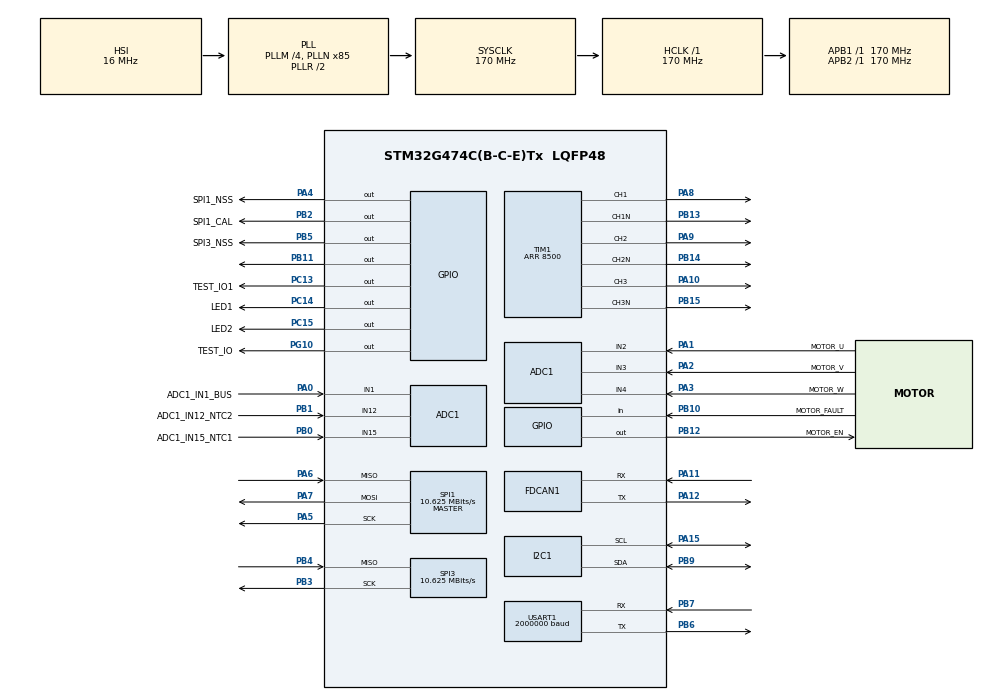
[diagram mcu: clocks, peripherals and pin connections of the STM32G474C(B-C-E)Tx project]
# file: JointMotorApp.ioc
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ADC1.Channel-0\#ChannelRegularConversion=ADC_CHANNEL_1
ADC1.Channel-6\#ChannelRegularConversion=ADC_CHANNEL_15
ADC1.Channel-7\#ChannelRegularConversion=ADC_CHANNEL_12
ADC1.ContinuousConvMode=DISABLE
ADC1.DMAContinuousRequests=ENABLE
ADC1.EOCSelection=ADC_EOC_SEQ_CONV
ADC1.EnableInjectedConversion=ENABLE
ADC1.ExternalTrigInjecConv=ADC_EXTERNALTRIGINJEC_T1_CC4
ADC1.InjNumberOfConversion=3
ADC1.InjectedChannel-3\#ChannelInjectedConversion=ADC_CHANNEL_2
ADC1.InjectedChannel-4\#ChannelInjectedConversion=ADC_CHANNEL_3
ADC1.InjectedChannel-5\#ChannelInjectedConversion=ADC_CHANNEL_4
ADC1.InjectedOffsetNumber-3\#ChannelInjectedConversion=ADC_OFFSET_NONE
ADC1.InjectedOffsetNumber-4\#ChannelInjectedConversion=ADC_OFFSET_NONE
ADC1.InjectedOffsetNumber-5\#ChannelInjectedConversion=ADC_OFFSET_NONE
ADC1.InjectedRank-3\#ChannelInjectedConversion=1
ADC1.InjectedRank-4\#ChannelInjectedConversion=2
ADC1.InjectedRank-5\#ChannelInjectedConversion=3
ADC1.InjectedSamplingTime-3\#ChannelInjectedConversion=ADC_SAMPLETIME_12CYCLES_5
ADC1.InjectedSamplingTime-4\#ChannelInjectedConversion=ADC_SAMPLETIME_12CYCLES_5
ADC1.InjectedSamplingTime-5\#ChannelInjectedConversion=ADC_SAMPLETIME_12CYCLES_5
ADC1.NbrOfConversion=3
ADC1.NbrOfConversionFlag=1
ADC1.OffsetNumber-0\#ChannelRegularConversion=ADC_OFFSET_NONE
ADC1.OffsetNumber-6\#ChannelRegularConversion=ADC_OFFSET_NONE
ADC1.OffsetNumber-7\#ChannelRegularConversion=ADC_OFFSET_NONE
ADC1.Rank-0\#ChannelRegularConversion=1
ADC1.Rank-6\#ChannelRegularConversion=2
ADC1.Rank-7\#ChannelRegularConversion=3
ADC1.SamplingTime-0\#ChannelRegularConversion=ADC_SAMPLETIME_47CYCLES_5
ADC1.SamplingTime-6\#ChannelRegularConversion=ADC_SAMPLETIME_47CYCLES_5
ADC1.SamplingTime-7\#ChannelRegularConversion=ADC_SAMPLETIME_47CYCLES_5
ADC1.master=1
Dma.ADC1.2.Direction=DMA_PERIPH_TO_MEMORY
Dma.ADC1.2.EventEnable=DISABLE
Dma.ADC1.2.Instance=DMA1_Channel3
Dma.ADC1.2.MemDataAlignment=DMA_MDATAALIGN_WORD
Dma.ADC1.2.MemInc=DMA_MINC_ENABLE
Dma.ADC1.2.Mode=DMA_CIRCULAR
Dma.ADC1.2.PeriphDataAlignment=DMA_PDATAALIGN_HALFWORD
Dma.ADC1.2.PeriphInc=DMA_PINC_DISABLE
Dma.ADC1.2.Polarity=HAL_DMAMUX_REQ_GEN_RISING
Dma.ADC1.2.Priority=DMA_PRIORITY_LOW
Dma.ADC1.2.RequestNumber=1
Dma.ADC1.2.SignalID=NONE
Dma.ADC1.2.SyncEnable=DISABLE
Dma.ADC1.2.SyncPolarity=HAL_DMAMUX_SYNC_NO_EVENT
Dma.ADC1.2.SyncRequestNumber=1
Dma.ADC1.2.SyncSignalID=NONE
Dma.Request0=USART1_RX
Dma.Request1=USART1_TX
Dma.Request2=ADC1
Dma.USART1_RX.0.Direction=DMA_PERIPH_TO_MEMORY
Dma.USART1_RX.0.EventEnable=DISABLE
Dma.USART1_RX.0.Instance=DMA1_Channel1
Dma.USART1_RX.0.MemDataAlignment=DMA_MDATAALIGN_BYTE
Dma.USART1_RX.0.MemInc=DMA_MINC_ENABLE
Dma.USART1_RX.0.Mode=DMA_CIRCULAR
Dma.USART1_RX.0.PeriphDataAlignment=DMA_PDATAALIGN_BYTE
Dma.USART1_RX.0.PeriphInc=DMA_PINC_DISABLE
Dma.USART1_RX.0.Polarity=HAL_DMAMUX_REQ_GEN_RISING
Dma.USART1_RX.0.Priority=DMA_PRIORITY_LOW
Dma.USART1_RX.0.RequestNumber=1
Dma.USART1_RX.0.SignalID=NONE
Dma.USART1_RX.0.SyncEnable=DISABLE
Dma.USART1_RX.0.SyncPolarity=HAL_DMAMUX_SYNC_NO_EVENT
Dma.USART1_RX.0.SyncRequestNumber=1
Dma.USART1_RX.0.SyncSignalID=NONE
Dma.USART1_TX.1.Direction=DMA_MEMORY_TO_PERIPH
Dma.USART1_TX.1.EventEnable=DISABLE
Dma.USART1_TX.1.Instance=DMA1_Channel2
Dma.USART1_TX.1.MemDataAlignment=DMA_MDATAALIGN_BYTE
Dma.USART1_TX.1.MemInc=DMA_MINC_ENABLE
Dma.USART1_TX.1.Mode=DMA_NORMAL
Dma.USART1_TX.1.PeriphDataAlignment=DMA_PDATAALIGN_BYTE
Dma.USART1_TX.1.PeriphInc=DMA_PINC_DISABLE
Dma.USART1_TX.1.Polarity=HAL_DMAMUX_REQ_GEN_RISING
Dma.USART1_TX.1.Priority=DMA_PRIORITY_LOW
Dma.USART1_TX.1.RequestNumber=1
Dma.USART1_TX.1.SignalID=NONE
Dma.USART1_TX.1.SyncEnable=DISABLE
Dma.USART1_TX.1.SyncPolarity=HAL_DMAMUX_SYNC_NO_EVENT
Dma.USART1_TX.1.SyncRequestNumber=1
Dma.USART1_TX.1.SyncSignalID=NONE
FDCAN1.CalculateBaudRateNominal=999999
FDCAN1.CalculateTimeBitNominal=1000
FDCAN1.CalculateTimeQuantumNominal=58.82352941176471
FDCAN1.ClockDivider=FDCAN_CLOCK_DIV2
FDCAN1.NominalPrescaler=5
FDCAN1.NominalTimeSeg1=12
FDCAN1.NominalTimeSeg2=4
FREERTOS.Tasks01=defaultTask,0,128,StartDefaultTask,Default,NULL,Dynamic,NULL,NULL
FREERTOS.configTOTAL_HEAP_SIZE=16384
I2C1.Timing=0x40B285C2
Mcu.Family=STM32G4
Mcu.Name=STM32G474C(B-C-E)Tx
Mcu.Package=LQFP48
NVIC.ADC1_2_IRQn=true\:5\:0\:false\:false\:true\:true\:true\:true\:true
NVIC.DMA1_Channel1_IRQn=true\:5\:0\:false\:false\:true\:true\:false\:true\:true
NVIC.DMA1_Channel2_IRQn=true\:5\:0\:false\:false\:true\:true\:false\:true\:true
NVIC.DMA1_Channel3_IRQn=true\:5\:0\:false\:false\:true\:true\:false\:true\:true
NVIC.FDCAN1_IT0_IRQn=true\:5\:0\:false\:false\:true\:true\:true\:true\:true
NVIC.PriorityGroup=NVIC_PRIORITYGROUP_4
NVIC.TIM1_BRK_TIM15_IRQn=true\:5\:0\:false\:false\:true\:true\:true\:true\:true
NVIC.TIM1_UP_TIM16_IRQn=true\:5\:0\:false\:false\:true\:true\:true\:true\:true
NVIC.TIM2_IRQn=true\:5\:0\:false\:false\:true\:true\:true\:true\:true
NVIC.TIM5_IRQn=true\:5\:0\:false\:false\:true\:true\:true\:true\:true
NVIC.TIM7_DAC_IRQn=true\:15\:0\:false\:false\:true\:false\:false\:true\:true
NVIC.TimeBase=TIM7_DAC_IRQn
NVIC.TimeBaseIP=TIM7
NVIC.USART1_IRQn=true\:5\:0\:false\:false\:true\:true\:true\:true\:true
PA0.GPIO_Label=ADC1_IN1_BUS
PA0.Mode=IN1-Single-Ended
PA0.Signal=ADC1_IN1
PA1.GPIO_Label=MOTOR_U
PA1.Mode=IN2-Single-Ended
PA1.Signal=ADC1_IN2
PA10.Signal=S_TIM1_CH3
PA11.Mode=FDCAN_Activate
PA11.Signal=FDCAN1_RX
PA12.Mode=FDCAN_Activate
PA12.Signal=FDCAN1_TX
PA13.Mode=Serial_Wire
PA13.Signal=SYS_JTMS-SWDIO
PA14.Mode=Serial_Wire
PA14.Signal=SYS_JTCK-SWCLK
PA15.Mode=I2C
PA15.Signal=I2C1_SCL
PA2.GPIO_Label=MOTOR_V
PA2.Mode=IN3-Single-Ended
PA2.Signal=ADC1_IN3
PA3.GPIO_Label=MOTOR_W
PA3.Mode=IN4-Single-Ended
PA3.Signal=ADC1_IN4
PA4.GPIO_Label=SPI1_NSS
PA4.Signal=GPIO_Output
PA5.Mode=Full_Duplex_Master
PA5.Signal=SPI1_SCK
PA6.Mode=Full_Duplex_Master
PA6.Signal=SPI1_MISO
PA7.Mode=Full_Duplex_Master
PA7.Signal=SPI1_MOSI
PA8.Signal=S_TIM1_CH1
PA9.Signal=S_TIM1_CH2
PB0.GPIO_Label=ADC1_IN15_NTC1
PB0.Mode=IN15-Single-Ended
PB0.Signal=ADC1_IN15
PB1.GPIO_Label=ADC1_IN12_NTC2
PB1.Mode=IN12-Single-Ended
PB1.Signal=ADC1_IN12
PB10.GPIO_Label=MOTOR_FAULT
PB10.Signal=GPIO_Input
PB11.Signal=GPIO_Output
PB12.GPIO_Label=MOTOR_EN
PB12.Signal=GPIO_Output
PB13.Mode=PWM Generation1 CH1 CH1N
PB13.Signal=TIM1_CH1N
PB14.Mode=PWM Generation2 CH2 CH2N
PB14.Signal=TIM1_CH2N
PB15.Mode=PWM Generation3 CH3 CH3N
PB15.Signal=TIM1_CH3N
PB2.GPIO_Label=SPI1_CAL
PB2.Signal=GPIO_Output
PB3.Mode=RX_Only_Simplex_Unidirect_Master
PB3.Signal=SPI3_SCK
PB4.Mode=RX_Only_Simplex_Unidirect_Master
PB4.Signal=SPI3_MISO
PB5.GPIO_Label=SPI3_NSS
PB5.Signal=GPIO_Output
PB6.Mode=Asynchronous
PB6.Signal=USART1_TX
PB7.Mode=Asynchronous
PB7.Signal=USART1_RX
PB9.Mode=I2C
PB9.Signal=I2C1_SDA
PC13.GPIO_Label=TEST_IO1
PC13.Signal=GPIO_Output
PC14-OSC32_IN.GPIO_Label=LED1
PC14-OSC32_IN.Signal=GPIO_Output
PC15-OSC32_OUT.GPIO_Label=LED2
PC15-OSC32_OUT.Signal=GPIO_Output
PF0-OSC_IN.Mode=HSE-External-Oscillator
PF0-OSC_IN.Signal=RCC_OSC_IN
PF1-OSC_OUT.Mode=HSE-External-Oscillator
PF1-OSC_OUT.Signal=RCC_OSC_OUT
PG10-NRST.GPIO_Label=TEST_IO
PG10-NRST.Signal=GPIO_Output
ProjectManager.HeapSize=0x200
ProjectManager.StackSize=0x400
ProjectManager.TargetToolchain=MDK-ARM V5.32
RCC.ADC12Freq_Value=170000000
RCC.ADC345Freq_Value=170000000
RCC.AHBFreq_Value=170000000
RCC.APB1Freq_Value=170000000
RCC.APB1TimFreq_Value=170000000
RCC.APB2Freq_Value=170000000
RCC.APB2TimFreq_Value=170000000
RCC.CortexFreq_Value=170000000
RCC.EXTERNAL_CLOCK_VALUE=12288000
RCC.HCLKFreq_Value=170000000
RCC.HSE_VALUE=8000000
RCC.HSI48_VALUE=48000000
RCC.HSI_VALUE=16000000
RCC.LSE_VALUE=32768
RCC.PLLM=RCC_PLLM_DIV4
RCC.PLLN=85
RCC.SYSCLKFreq_VALUE=170000000
RCC.SYSCLKSource=RCC_SYSCLKSOURCE_PLLCLK
RCC.USBFreq_Value=170000000
RCC.VCOOutputFreq_Value=340000000
SH.S_TIM1_CH1.0=TIM1_CH1,PWM Generation1 CH1 CH1N
SH.S_TIM1_CH2.0=TIM1_CH2,PWM Generation2 CH2 CH2N
SH.S_TIM1_CH3.0=TIM1_CH3,PWM Generation3 CH3 CH3N
SPI1.BaudRatePrescaler=SPI_BAUDRATEPRESCALER_16
SPI1.CLKPhase=SPI_PHASE_2EDGE
SPI1.CLKPolarity=SPI_POLARITY_HIGH
SPI1.CalculateBaudRate=10.625 MBits/s
SPI1.DataSize=SPI_DATASIZE_8BIT
SPI1.Direction=SPI_DIRECTION_2LINES
SPI1.Mode=SPI_MODE_MASTER
SPI1.VirtualType=VM_MASTER
SPI3.BaudRatePrescaler=SPI_BAUDRATEPRESCALER_16
SPI3.CalculateBaudRate=10.625 MBits/s
SPI3.DataSize=SPI_DATASIZE_8BIT
SPI3.Direction=SPI_DIRECTION_2LINES_RXONLY
SPI3.Mode=SPI_MODE_MASTER
SPI3.VirtualType=VM_MASTER
STMicroelectronics.X-CUBE-ALGOBUILD.1.5.0.LibraryCcDSPOoLibraryJjDSPOoLibrary=true
TIM1.Channel-PWM\ Generation1\ CH1\ CH1N=TIM_CHANNEL_1
TIM1.Channel-PWM\ Generation2\ CH2\ CH2N=TIM_CHANNEL_2
TIM1.Channel-PWM\ Generation3\ CH3\ CH3N=TIM_CHANNEL_3
TIM1.Channel-PWM\ Generation4\ No\ Output=TIM_CHANNEL_4
TIM1.CounterMode=TIM_COUNTERMODE_CENTERALIGNED1
TIM1.PeriodNoDither=8500
TIM2.PeriodNoDither=17000
TIM5.PeriodNoDither=17000
USART1.BaudRate=2000000
USART1.VirtualMode-Asynchronous=VM_ASYNC
VP_CORDIC_VS_CORDIC.Mode=CORDIC_Activate
VP_FREERTOS_VS_CMSIS_V1.Mode=CMSIS_V1
VP_STMicroelectronics.X-CUBE-ALGOBUILD_VS_DSPOoLibraryJjLibrary_1.5.0_1.5.0.Mode=DSPOoLibraryJjLibrary
VP_SYS_VS_DBSignals.Mode=DisableDeadBatterySignals
VP_SYS_VS_tim7.Mode=TIM7
VP_TIM1_VS_no_output4.Mode=PWM Generation4 No Output
VP_TIM2_VS_ClockSourceINT.Mode=Internal
VP_TIM5_VS_ClockSourceINT.Mode=Internal
board=custom

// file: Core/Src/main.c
/* USER CODE BEGIN Header */
/**
  ******************************************************************************
  * @file           : main.c
  * @brief          : Main program body
  ******************************************************************************
  * @attention
  *
  * Copyright (c) 2026 STMicroelectronics.
  * All rights reserved.
  *
  * This software is licensed under terms that can be found in the LICENSE file
  * in the root directory of this software component.
  * If no LICENSE file comes with this software, it is provided AS-IS.
  *
  ******************************************************************************
  */
/* USER CODE END Header */
#include "main.h"
#include "cmsis_os.h"
#include "adc.h"
#include "cordic.h"
#include "dma.h"
#include "fdcan.h"
#include "i2c.h"
#include "spi.h"
#include "tim.h"
#include "usart.h"
#include "gpio.h"

/* USER CODE BEGIN Includes */
#include "user_interface.h"
/* USER CODE END Includes */

void SystemClock_Config(void);
void MX_FREERTOS_Init(void);

int main(void)
{

  /* MCU Configuration--------------------------------------------------------*/

  /* Reset of all peripherals, Initializes the Flash interface and the Systick. */
  HAL_Init();

  /* Configure the system clock */
  SystemClock_Config();

  /* Initialize all configured peripherals */
  MX_GPIO_Init();
  MX_DMA_Init();
  MX_ADC1_Init();
  MX_CORDIC_Init();
  MX_I2C1_Init();
  MX_SPI1_Init();
  MX_SPI3_Init();
  MX_USART1_UART_Init();
  MX_FDCAN1_Init();
  MX_TIM1_Init();
  MX_TIM2_Init();
  MX_TIM5_Init();
  /* USER CODE BEGIN 2 */

	user_init();

  /* USER CODE END 2 */

  /* Call init function for freertos objects (in cmsis_os2.c) */
  MX_FREERTOS_Init();

  /* Start scheduler */
  osKernelStart();

  /* We should never get here as control is now taken by the scheduler */

  /* Infinite loop */
	while (1)
	{

	}
}

void SystemClock_Config(void)
{
  RCC_OscInitTypeDef RCC_OscInitStruct = {0};
  RCC_ClkInitTypeDef RCC_ClkInitStruct = {0};

  /** Configure the main internal regulator output voltage
  */
  HAL_PWREx_ControlVoltageScaling(PWR_REGULATOR_VOLTAGE_SCALE1_BOOST);

  /** Initializes the RCC Oscillators according to the specified parameters
  * in the RCC_OscInitTypeDef structure.
  */
  RCC_OscInitStruct.OscillatorType = RCC_OSCILLATORTYPE_HSI;
  RCC_OscInitStruct.HSIState = RCC_HSI_ON;
  RCC_OscInitStruct.HSICalibrationValue = RCC_HSICALIBRATION_DEFAULT;
  RCC_OscInitStruct.PLL.PLLState = RCC_PLL_ON;
  RCC_OscInitStruct.PLL.PLLSource = RCC_PLLSOURCE_HSI;
  RCC_OscInitStruct.PLL.PLLM = RCC_PLLM_DIV4;
  RCC_OscInitStruct.PLL.PLLN = 85;
  RCC_OscInitStruct.PLL.PLLP = RCC_PLLP_DIV2;
  RCC_OscInitStruct.PLL.PLLQ = RCC_PLLQ_DIV2;
  RCC_OscInitStruct.PLL.PLLR = RCC_PLLR_DIV2;
  if (HAL_RCC_OscConfig(&RCC_OscInitStruct) != HAL_OK)
  {
    Error_Handler();
  }

  /** Initializes the CPU, AHB and APB buses clocks
  */
  RCC_ClkInitStruct.ClockType = RCC_CLOCKTYPE_HCLK|RCC_CLOCKTYPE_SYSCLK
                              |RCC_CLOCKTYPE_PCLK1|RCC_CLOCKTYPE_PCLK2;
  RCC_ClkInitStruct.SYSCLKSource = RCC_SYSCLKSOURCE_PLLCLK;
  RCC_ClkInitStruct.AHBCLKDivider = RCC_SYSCLK_DIV1;
  RCC_ClkInitStruct.APB1CLKDivider = RCC_HCLK_DIV1;
  RCC_ClkInitStruct.APB2CLKDivider = RCC_HCLK_DIV1;

  if (HAL_RCC_ClockConfig(&RCC_ClkInitStruct, FLASH_LATENCY_4) != HAL_OK)
  {
    Error_Handler();
  }
}

void HAL_TIM_PeriodElapsedCallback(TIM_HandleTypeDef *htim)
{
  /* USER CODE BEGIN Callback 0 */
	if (htim->Instance == TIM2)
	{
		user_control();
	}
	if (htim->Instance == TIM5)
	{
		motor_virtual_loop();
	}
  /* USER CODE END Callback 0 */
  if (htim->Instance == TIM7)
  {
    HAL_IncTick();
  }
}

void Error_Handler(void)
{
	__disable_irq();
	while (1)
	{
	}
}
